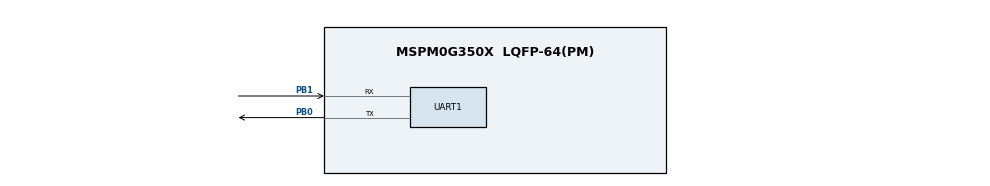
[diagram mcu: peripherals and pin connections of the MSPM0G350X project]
/**
 * @cliArgs --device "MSPM0G350X" --package "LQFP-64(PM)" --part "Default" --product "mspm0_sdk@1.30.00.03"
 * @versions {"tool":"1.20.0+3587"}
 */

/**
 * Import the modules used in this configuration.
 */
const ADC12         = scripting.addModule("/ti/driverlib/ADC12", {}, false);
const ADC121        = ADC12.addInstance();
const MATHACL       = scripting.addModule("/ti/driverlib/MATHACL");
const SYSCTL        = scripting.addModule("/ti/driverlib/SYSCTL");
const TIMER         = scripting.addModule("/ti/driverlib/TIMER", {}, false);
const TIMER1        = TIMER.addInstance();
const UART          = scripting.addModule("/ti/driverlib/UART", {}, false);
const UART1         = UART.addInstance();
const ProjectConfig = scripting.addModule("/ti/project_config/ProjectConfig");

/**
 * Write custom configuration values to the imported modules.
 */
const divider9       = system.clockTree["UDIV"];
divider9.divideValue = 2;

const multiplier2         = system.clockTree["PLL_QDIV"];
multiplier2.multiplyValue = 4;

const mux4       = system.clockTree["EXHFMUX"];
mux4.inputSelect = "EXHFMUX_XTAL";

const mux5       = system.clockTree["EXLFMUX"];
mux5.inputSelect = "EXLFMUX_XTAL";

const mux8       = system.clockTree["HSCLKMUX"];
mux8.inputSelect = "HSCLKMUX_SYSPLL0";

const mux12       = system.clockTree["SYSPLLMUX"];
mux12.inputSelect = "zSYSPLLMUX_HFCLK";

const pinFunction4        = system.clockTree["HFXT"];
pinFunction4.inputFreq    = 40;
pinFunction4.enable       = true;
pinFunction4.HFXTStartup  = 10;
pinFunction4.HFCLKMonitor = true;

const pinFunction6     = system.clockTree["LFXT"];
pinFunction6.inputFreq = 40;

ADC121.$name                             = "ADC12_0";
ADC121.repeatMode                        = true;
ADC121.trigSrc                           = "DL_ADC12_TRIG_SRC_EVENT";
ADC121.adcMem0trig                       = "DL_ADC12_TRIGGER_MODE_TRIGGER_NEXT";
ADC121.powerDownMode                     = "DL_ADC12_POWER_DOWN_MODE_MANUAL";
ADC121.sampleTime0                       = "62.5 ns";
ADC121.enabledInterrupts                 = ["DL_ADC12_INTERRUPT_DMA_DONE"];
ADC121.configureDMA                      = true;
ADC121.sampCnt                           = 1;
ADC121.enabledDMATriggers                = ["DL_ADC12_DMA_MEM0_RESULT_LOADED"];
ADC121.subChanID                         = 1;
ADC121.adcMem0chansel                    = "DL_ADC12_INPUT_CHAN_2";
ADC121.peripheral.$assign                = "ADC0";
ADC121.DMA_CHANNEL.$name                 = "DMA_CH0";
ADC121.DMA_CHANNEL.addressMode           = "f2b";
ADC121.DMA_CHANNEL.srcLength             = "HALF_WORD";
ADC121.DMA_CHANNEL.dstLength             = "HALF_WORD";
ADC121.DMA_CHANNEL.configureTransferSize = true;
ADC121.DMA_CHANNEL.transferMode          = "FULL_CH_REPEAT_SINGLE";
ADC121.DMA_CHANNEL.transferSize          = 1024;
ADC121.adcPin2Config.$name               = "ti_driverlib_gpio_GPIOPinGeneric0";

const Board = scripting.addModule("/ti/driverlib/Board", {}, false);

SYSCTL.forceDefaultClkConfig = true;
SYSCTL.clockTreeEn           = true;

TIMER1.$name                       = "TIMER_0";
TIMER1.timerMode                   = "PERIODIC";
TIMER1.timerPeriod                 = "5 us";
TIMER1.timerStartTimer             = true;
TIMER1.event1PublisherChannel      = 1;
TIMER1.event1ControllerInterruptEn = ["ZERO_EVENT"];

UART1.$name                    = "UART_0";
UART1.targetBaudRate           = 115200;
UART1.peripheral.rxPin.$assign = "PB1";
UART1.peripheral.txPin.$assign = "PB0";
UART1.txPinConfig.$name        = "ti_driverlib_gpio_GPIOPinGeneric1";
UART1.rxPinConfig.$name        = "ti_driverlib_gpio_GPIOPinGeneric2";

ProjectConfig.genLibIQ        = true;
ProjectConfig.genLibCMSIS     = true;
ProjectConfig.genLibIQVersion = "MATHACL";

/**
 * Pinmux solution for unlocked pins/peripherals. This ensures that minor changes to the automatic solver in a future
 * version of the tool will not impact the pinmux you originally saw.  These lines can be completely deleted in order to
 * re-solve from scratch.
 */
pinFunction4.peripheral.$suggestSolution           = "SYSCTL";
pinFunction4.peripheral.hfxInPin.$suggestSolution  = "PA5";
pinFunction4.peripheral.hfxOutPin.$suggestSolution = "PA6";
ADC121.peripheral.adcPin2.$suggestSolution         = "PA25";
ADC121.DMA_CHANNEL.peripheral.$suggestSolution     = "DMA_CH0";
Board.peripheral.$suggestSolution                  = "DEBUGSS";
Board.peripheral.swclkPin.$suggestSolution         = "PA20";
Board.peripheral.swdioPin.$suggestSolution         = "PA19";
TIMER1.peripheral.$suggestSolution                 = "TIMA0";
UART1.peripheral.$suggestSolution                  = "UART0";
